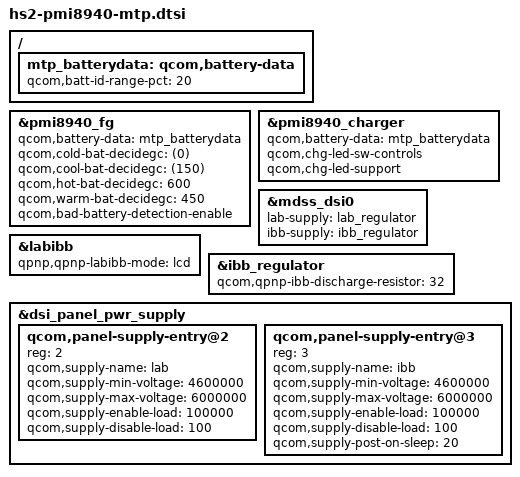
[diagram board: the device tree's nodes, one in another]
/*
 * Copyright (c) 2017, The Linux Foundation. All rights reserved.
 *
 * This program is free software; you can redistribute it and/or modify
 * it under the terms of the GNU General Public License version 2 and
 * only version 2 as published by the Free Software Foundation.
 *
 * This program is distributed in the hope that it will be useful,
 * but WITHOUT ANY WARRANTY; without even the implied warranty of
 * MERCHANTABILITY or FITNESS FOR A PARTICULAR PURPOSE.  See the
 * GNU General Public License for more details.
 */

#include "hs2-msm-pmi8940.dtsi"
#include "hs2-mdss.dtsi"
#include "hs2-pinctrl.dtsi"
#include "hs2.dtsi"
#include "hs2-mtp.dtsi"
#include "hs2-audio.dtsi"
#include "hs2-audio-mtp.dtsi"
#include "hs2-camera-pinctrl.dtsi"
#include "hs2-camera-sensor-mtp.dtsi"

/{
	mtp_batterydata: qcom,battery-data {
		qcom,batt-id-range-pct = <20>; //change for battery detect 
		#include "batterydata-tinno-2900mah-4400mv.dtsi"
	};
};

&pmi8940_fg {
	qcom,battery-data = <&mtp_batterydata>;
	qcom,cold-bat-decidegc = <(0)>;
	qcom,cool-bat-decidegc = <(150)>;
	qcom,hot-bat-decidegc = <600>;
	qcom,warm-bat-decidegc = <450>;	
	qcom,bad-battery-detection-enable;
};

&pmi8940_charger {
	qcom,battery-data = <&mtp_batterydata>;
	qcom,chg-led-sw-controls;
	qcom,chg-led-support;
};

&mdss_dsi0 {
	lab-supply = <&lab_regulator>;
	ibb-supply = <&ibb_regulator>;
};

&labibb {
	status = "ok";
	qpnp,qpnp-labibb-mode = "lcd";
};

&ibb_regulator {
	qcom,qpnp-ibb-discharge-resistor = <32>;
};

&dsi_panel_pwr_supply {
	qcom,panel-supply-entry@2 {
		reg = <2>;
		qcom,supply-name = "lab";
		qcom,supply-min-voltage = <4600000>;
		qcom,supply-max-voltage = <6000000>;
		qcom,supply-enable-load = <100000>;
		qcom,supply-disable-load = <100>;
	};

	qcom,panel-supply-entry@3 {
		reg = <3>;
		qcom,supply-name = "ibb";
		qcom,supply-min-voltage = <4600000>;
		qcom,supply-max-voltage = <6000000>;
		qcom,supply-enable-load = <100000>;
		qcom,supply-disable-load = <100>;
		qcom,supply-post-on-sleep = <20>;
	};
};
